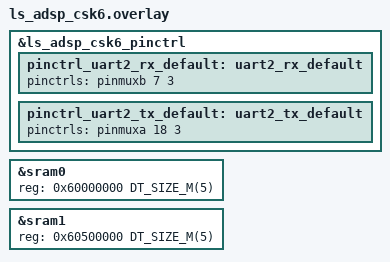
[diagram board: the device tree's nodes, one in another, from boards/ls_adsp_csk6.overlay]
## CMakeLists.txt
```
cmake_minimum_required(VERSION 3.20.0)

# SPDX-License-Identifier: Apache-2.0
#

if("${BOARD}" STREQUAL "ls_adsp_csk6")
set(ENV{ZEPHYR_TOOLCHAIN_VARIANT} "xcc-clang")
endif()

if("${BOARD}" STREQUAL "ls_adsp_csk6")
	message(STATUS " ${REMOTE_ZEPHYR_DIR} compiles as remote in this sample")
else()
	message(FATAL_ERROR "${BOARD} was not supported for this sample")
endif()
find_package(Zephyr HINTS $ENV{ZEPHYR_BASE})
project(sof_remote)


zephyr_include_directories(
  ./include
  ./include/luna/
  ./include/hifi/
  ./include/hifi_sim/
  ./include/opi_cpy/
  ./include/pilot/
  ./include/img/
  ./include/pilot_app/
)

if(NOT CONFIG_ALGO_RES_BIN)
	message(STATUS "CONFIG_ALGO_RES_BIN is not defined")
	zephyr_include_directories(./include/res/)
else()
message(STATUS "generating inc file")
	set(gen_dir ${ZEPHYR_BINARY_DIR}/include/generated)

	foreach(inc_file
		gesture.bin
		head_shoulder_detect.bin
		)
	generate_inc_file_for_target(
		app
		res/${inc_file}
		${gen_dir}/${inc_file}.inc
		)
	endforeach()

endif()

target_sources(app PRIVATE
    src/main.c
    src/opi_psram_cpy.c
    src/pilot_app.c
    src/test_cvtcolor.c
    src/cv_cvtcolor.c
  )


set(LIB_DIR  ${CMAKE_CURRENT_SOURCE_DIR}/lib)

target_link_libraries(app PUBLIC -Wl,--start-group 
						 -lgcc 
						 -lc 
						 -lm 
						 -lgloss 
						 -lminrt 
						 ${LIB_DIR}/libopi_cpy.a 
             			 ${LIB_DIR}/libhifi_dsp.a 
						 ${LIB_DIR}/libluna.a 
						 ${LIB_DIR}/libthinker.a 
						 ${LIB_DIR}/libpilot.a 
						 -Wl,--end-group)
```

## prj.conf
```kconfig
# CONFIG_SOF=y
CONFIG_LOG=y
CONFIG_LOG_PRINTK=y
CONFIG_LOG_MODE_MINIMAL=y

CONFIG_BUILD_OUTPUT_BIN=y
CONFIG_IPM=y
# Requires heap_info() be implemented, but no Zephyr wrapper
CONFIG_DEBUG_MEMORY_USAGE_SCAN=n

CONFIG_SCHED_DEADLINE=y
CONFIG_SCHED_CPU_MASK=y
CONFIG_SMP_BOOT_DELAY=y

CONFIG_DMA=y

CONFIG_CBPRINTF_FP_SUPPORT=y

CONFIG_ASSERT=y

CONFIG_EXTERNAL_LIBC=y
CONFIG_STDOUT_CONSOLE=n

CONFIG_STACK_SENTINEL=y

CONFIG_HEAP_MEM_POOL_SIZE=3145728
CONFIG_MAIN_STACK_SIZE=10240
```

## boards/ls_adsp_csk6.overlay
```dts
&ls_adsp_csk6_pinctrl{
        pinctrl_uart2_rx_default: uart2_rx_default {
			pinctrls = < &pinmuxb 7 3 >;
		};

		pinctrl_uart2_tx_default: uart2_tx_default {
			pinctrls = < &pinmuxa 18 3 >;
		};
};

&sram0 {
	reg = <0x60000000 DT_SIZE_M(5)>;
};

&sram1 {
	reg = <0x60500000 DT_SIZE_M(5)>;
};
```

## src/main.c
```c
/*
 * Copyright (c) 2020 Intel Corporation.
 *
 * SPDX-License-Identifier: Apache-2.0
 */

#include <zephyr.h>

#include <logging/log.h>
#include <w_pilot_err.h>
#include <pilot_app.h>
#include <venus_cp.h>
#include <luna_bits.h>
#include <ClockManager.h>

LOG_MODULE_REGISTER(main, LOG_LEVEL_DBG);

extern void test_cvt_yuv();
//CSK star app
int start_app(void)
{
	printk("Starting application_note\n");
	printk("Starting application_note2\n");
	test_cvt_yuv();
	// int ret_error = IPILOT_SUCCESS;
	// IPLT_INST ifr_inst = NULL;
	// //init
	// ret_error = INIT_ENGINE(&ifr_inst);
	// //set params
	// SET_PARMA_ENGINE(ifr_inst);
	// //test
	// CSK_test_function(ifr_inst);
	// //unint
	// ret_error = UINIT_ENGINE(ifr_inst);



	return 0;
}

extern void luna_init();
void sys_init(void)
{
    // enable NPU Clock
	__HAL_CRM_NPU_CLK_ENABLE();

    // release NPU
    if(IP_SYSCTRL->REG_SW_RESET_NPU.all){
        IP_SYSCTRL->REG_SW_RESET_NPU.all = 0xCAFE000C;
    }
    luna_init();

	uint32_t luna_val = *((volatile uint32_t *)(ADDR_LUNA_MODULE_ST));

	LOG_INF("luna_val: %d", luna_val);
}


extern void dma_init();
void main(void)
{

	LOG_INF("pilot app start");

	dma_init();
	sys_init();
	start_app();

}
```

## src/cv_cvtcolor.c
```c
#if defined(CSK6001)
#include <xtensa/config/core-isa.h>
#include <xtensa/tie/xt_core.h>
#include <xtensa/tie/xt_misc.h>
#include <xtensa/tie/xt_hifi3.h>
#include <xtensa/tie/xt_hifi4.h>
#else
#include "common.h"
#endif 

#include "hifi/NatureDSP_CV_math.h"

void cv_cvtcolor_yuv422vyuy_bgr888(const unsigned char* src, unsigned char* dst, unsigned int width, unsigned int height)
{
	int i, j, k;
	ae_int16x4 x0, x1, y0, v0, u0, xh0;
	ae_int32x2 z00, z01, z10, z11, z20, z21;
	ae_int24x2 z0, z1;
	ae_int16x4* px;
	ae_int24x2* pz;
	ae_int16x4 x256 = AE_MOVDA16(256);
	ae_int16x4 x128 = AE_MOVDA16(128);
	ae_int16x4 x359 = AE_MOVDA16(359);
	ae_int16x4 x183 = AE_MOVDA16(-183);
	ae_int16x4 x444 = AE_MOVDA16(444);
	ae_int16x4 x88 = AE_MOVDA16(-88);
	ae_int16x4 xff = AE_MOVDA16(0xff);
	ae_int32x2 zmask0 = AE_MOVDA32(0xff);
	ae_int32x2 zmask1 = AE_MOVDA32(0xff00);
	ae_int32x2 zmask2 = AE_MOVDA32(0xff0000);

	unsigned int z;
	const unsigned char* yuv_plane = src;
	unsigned char* rgb_plane = dst;

	px = (ae_int16x4*)yuv_plane;
	pz = (ae_int24x2*)rgb_plane;

	NASSERT(((uintptr_t)src & 0x7) == 0);
	NASSERT(((uintptr_t)dst & 0x7) == 0);
	NASSERT((width & 0x3) == 0);

	AE_L16X4_IP(xh0, px, 8);
	ae_valign zo_align = AE_ZALIGN64();

	for (int j = 0; j < ((height*width) >> 2); j++)
	{
		x0 = xh0;

		x1 = AE_AND16(x0, xff);
		y0 = AE_SLAA16S(x0, -8);
		y0 = AE_AND16(y0, xff);
		//y0 = AE_MOVINT16X4_FROMINT64((AE_SRLI64(AE_MOVINT64_FROMINT16X4(x0), 8)));

		x0 = AE_SEL16_7632(x1, x1);
		x1 = AE_SEL16_5410(x1, x1);
		v0 = AE_SEL16_7531(x0, x1);
		u0 = AE_SEL16_6420(x0, x1);
		v0 = AE_SUB16(v0, x128);
		u0 = AE_SUB16(u0, x128);

		//R
		AE_MUL16X4(z00, z01, y0, x256);
		//z10 = z00; z11 = z01;
		AE_MULA16X4(z00, z01, v0, x359);
		//G
		AE_MUL16X4(z10, z11, y0, x256);
		//z20 = z10; z21 = z11;
		AE_MULA16X4(z10, z11, v0, x183);
		AE_MULA16X4(z10, z11, u0, x88);
		//B
		AE_MUL16X4(z20, z21, y0, x256);
		AE_MULA16X4(z20, z21, u0, x444);
		AE_L16X4_IP(xh0, px, 8);

		//L->H:BGR0
		z00 = AE_AND32(AE_SLAA32S(z00, 8), zmask2);//H ((>>8)<<16)
		z10 = AE_AND32(z10, zmask1); //((>>8)<<8)
		z20 = AE_AND32(AE_SLAA32S(z20, -8), zmask0);//L
		z00 = AE_OR32(z00, AE_OR32(z10, z20));
		z0 = AE_MOVINT24X2_FROMF32X2(z00);
		AE_SA24X2_IP(z0, zo_align, pz);

		z01 = AE_AND32(AE_SLAA32S(z01, 8), zmask2);
		z11 = AE_AND32(z11, zmask1);
		z21 = AE_AND32(AE_SLAA32S(z21, -8), zmask0);
		z01 = AE_OR32(z01, AE_OR32(z11, z21));
		z1 = AE_MOVINT24X2_FROMF32X2(z01);
		AE_SA24X2_IP(z1, zo_align, pz);
	}
	AE_SA64POS_FP(zo_align, pz);
}
```

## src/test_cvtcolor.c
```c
#include "hifi/NatureDSP_CV_math.h"
#include "hifi_sim/NatureDSP_CV_math.h"


#include <luna.h>

#define ALIGNN(n,a)	((n+(a-1))&~(a-1))
#define MALLOCA(p, s, a)		(char*)(ALIGNN((uintptr_t)(p), a)); (p) = (char*)ALIGNN((uintptr_t)(p), a) + (s);
// #define printk printf;


void HIFI_SIM(cv_cvtcolor_yuv422vyuy_bgr888_dma)(const unsigned char* src, unsigned char* dst, unsigned int width, unsigned int height, unsigned int split_num,
	unsigned char* sharebuf, unsigned int sharesize)
{
	int i, j, k;
	int n = split_num; //8
	int block_size = width * height / n;
	unsigned char *p_block_s0 = sharebuf;
	unsigned char *p_block_s1 = p_block_s0 + block_size * 2;
	unsigned char *p_block_d0 = p_block_s1 + block_size * 2;
	unsigned char *p_block_d1 = p_block_d0 + block_size * 3;
	NASSERT(p_block_d1 - sharebuf <= sharesize);
	NASSERT((width * height) % n == 0);
	NASSERT((height / n) % 2 == 0);

	for (k = 0; k < n; k++)
	{
		unsigned char* p_block_s = (unsigned char*)src + k*block_size * 2;
		unsigned char* p_block_d = dst + k*block_size * 3;
		memcpy(p_block_s0, p_block_s, block_size * 2);
		cv_cvtcolor_yuv422vyuy_bgr888(p_block_s0, p_block_d0, width, height / n);
		memcpy(p_block_d, p_block_d0, block_size * 3);
	}
}

void cv_cvtcolor_yuv422vyuy_bgr888_dma(const unsigned char* src, unsigned char* dst, unsigned int width, unsigned int height, unsigned int split_num,
	unsigned char* sharebuf, unsigned int sharesize)
{
	int i, j, k;
	int n = split_num; //8
	int block_size = width * height / n;
	int block_size1 = block_size / 2;
	unsigned char *p_block_s0 = sharebuf;
	unsigned char *p_block_s1 = p_block_s0 + block_size * 2;
	unsigned char *p_block_d0 = p_block_s1 + block_size * 2;
	unsigned char *p_block_d1 = p_block_d0 + block_size * 3;
	NASSERT(p_block_d1 - sharebuf <= sharesize);
	NASSERT((width * height) % n == 0);
	NASSERT((height/ n) % 2 == 0);

	unsigned char* p_block_s = (unsigned char*)src + (n - 1)*block_size * 2;
	unsigned char* p_block_d = dst + (n - 1)*block_size * 3;
	unsigned char* p_block_ss, *p_block_dd;

	for (k = 0; k < n; k++)
	{
		if (k == 0)
		{
			p_block_ss = p_block_s0;
			p_block_dd = p_block_d0;
			//start_counter();
			dma_cpy_async(0, p_block_s0, p_block_s, block_size * 2);
			dma_wait_complete(0);
			p_block_s -= block_size * 2;
			//printk("counter1 = %d\n", get_counter());

			//start_counter();
			cv_cvtcolor_yuv422vyuy_bgr888(p_block_ss, p_block_dd, width, height / n / 2);
			//printk("counter1 = %d\n", get_counter());

			dma_cpy_async(0, p_block_s1, p_block_s, block_size * 2);
			cv_cvtcolor_yuv422vyuy_bgr888(p_block_ss + block_size / 2 * 2, p_block_dd + block_size / 2 * 3, width, height / n / 2);
			dma_wait_complete(0);
			p_block_s -= block_size * 2;
		}
		else if (k == n - 1)
		{
			p_block_ss = p_block_s1;
			p_block_dd = p_block_d1;

			dma_cpy_async(0, p_block_d, p_block_d0, block_size * 3);
			cv_cvtcolor_yuv422vyuy_bgr888(p_block_ss, p_block_dd, width, height / n / 2);
			dma_wait_complete(0);
			p_block_d -= block_size * 3;

			cv_cvtcolor_yuv422vyuy_bgr888(p_block_ss + block_size / 2 * 2, p_block_dd + block_size / 2 * 3, width, height / n / 2);

			//start_counter();
			dma_cpy_async(0, p_block_d, p_block_d1, block_size * 3);
			dma_wait_complete(0);
			p_block_d -= block_size * 3;
			//printk("counter1 = %d\n", get_counter());
		}
		else if (k % 2 == 0)
		{
			p_block_ss = p_block_s0;
			p_block_dd = p_block_d0;

			dma_cpy_async(0, p_block_s1, p_block_s, block_size * 2);
			cv_cvtcolor_yuv422vyuy_bgr888(p_block_ss, p_block_dd, width, height / n / 2);
			dma_wait_complete(0);

			dma_cpy_async(0, p_block_d, p_block_d1, block_size * 3);
			cv_cvtcolor_yuv422vyuy_bgr888(p_block_ss + block_size / 2 * 2, p_block_dd + block_size / 2 * 3, width, height / n / 2);
			dma_wait_complete(0);

			p_block_s -= block_size * 2;
			p_block_d -= block_size * 3;
		}
		else
		{
			p_block_ss = p_block_s1;
			p_block_dd = p_block_d1;

			dma_cpy_async(0, p_block_s0, p_block_s, block_size * 2);
			cv_cvtcolor_yuv422vyuy_bgr888(p_block_ss, p_block_dd, width, height / n / 2);
			dma_wait_complete(0);

			dma_cpy_async(0, p_block_d, p_block_d0, block_size * 3);
			cv_cvtcolor_yuv422vyuy_bgr888(p_block_ss + block_size / 2 * 2, p_block_dd + block_size / 2 * 3, width, height / n / 2);
			dma_wait_complete(0);

			p_block_s -= block_size * 2;
			p_block_d -= block_size * 3;
		}
	}
}


/*

test_cvt_yuv begin...
//CP:200M
//320x240
cv_cvtcolor_yuv422vyuy_bgr888_sim(psram) = 916745
cv_cvtcolor_yuv422vyuy_bgr888(psram) = 820280
cv_cvtcolor_yuv422vyuy_bgr888_sim(share) = 883423
cv_cvtcolor_yuv422vyuy_bgr888(share) = 326564
//640x480
cv_cvtcolor_yuv422vyuy_bgr888_dma_sim = 3726385
cv_cvtcolor_yuv422vyuy_bgr888_dma = 1471809
z1 = 0x6012f680, z2 = 0x60210680, size = 230400
test_cvt_yuv end...

*/
#define PSRAM_INST_SIZE (1*1024*1024)
#define SHARE_MEME_SIZE (640*1024)
static char g_psram_inst_buffer[PSRAM_INST_SIZE];
void test_cvt_yuv()
{
	printk("\ntest_cvt_yuv\n");
	
	clock_t last_t;
	char* p_psram = g_psram_inst_buffer;
	char* p_share = (char *)LUNA_SHARE_MEM_BASE;
	const unsigned int srcw = 640;
	const unsigned int srch = 480;
	const unsigned int dstw = 640;
	const unsigned int dsth = 480;
	unsigned int crc32;
	extern struct k_heap _system_heap;
// rzalloc(SOF_MEM_ZONE_RUNTIME, 0, SOF_MEM_CAPS_RAM, 3 * srcw*srch * 1);
	uint8_t* x = (uint8_t *)sys_heap_aligned_alloc(&_system_heap , 8,3 * srcw*srch * 1);
	ASSERT( x!=0);
	uint8_t* z1 = (uint8_t *)sys_heap_aligned_alloc(&_system_heap ,8,3 * srcw*srch * 1);
	ASSERT( z1!=0);
	uint8_t* z2 = (uint8_t *)sys_heap_aligned_alloc(&_system_heap ,8,3 * srcw*srch * 1);
		
	ASSERT( z2!=0);
	// for (int i = 0; i < 3 * srcw*srch; i++)
	// {
	// 	x[i] = rand() % 255;
	// }
	// ((unsigned char*)x)[0] = 129;

	printk("%s begin...\n", __FUNCTION__);

	//
	last_t = clock();
	// cv_cvtcolor_yuv422vyuy_bgr888_sim(x, z1, srcw / 2, srch / 2); 
	printk("cv_cvtcolor_yuv422vyuy_bgr888_sim(psram) = %d\n", clock() - last_t);

	last_t = clock();
	cv_cvtcolor_yuv422vyuy_bgr888(x, z2, srcw / 2, srch / 2);
	printk("cv_cvtcolor_yuv422vyuy_bgr888(psram) = %d\n", clock() - last_t);

	ASSERT(test_cmp(z1, z2, 3 * dstw / 2 * dsth / 2, 0x11) == 0);

	//
	last_t = clock();
	// cv_cvtcolor_yuv422vyuy_bgr888_sim((unsigned char*)p_share, (unsigned char*)p_share, srcw / 2, srch / 2);
	printk("cv_cvtcolor_yuv422vyuy_bgr888_sim(share) = %d\n", clock() - last_t);

	last_t = clock();
	cv_cvtcolor_yuv422vyuy_bgr888((unsigned char*)p_share, (unsigned char*)p_share, srcw / 2, srch / 2); 
	printk("cv_cvtcolor_yuv422vyuy_bgr888(share) = %d\n", clock() - last_t);

	//dma
	cv_cvtcolor_yuv422vyuy_bgr888(x, z1, srcw, srch);

	last_t = clock();
	// cv_cvtcolor_yuv422vyuy_bgr888_dma_sim(x, z2, srcw, srch, 16, (unsigned char*)p_share, 640 * 1024);
	printk("cv_cvtcolor_yuv422vyuy_bgr888_dma_sim = %d\n", clock() - last_t);
	// NASSERT(test_cmp(z1, z2, 3 * dstw * dsth, 0x11) == 0);

	//memcpy(z2, x, srcw*srch * 2);
	dma_cpy_async(0, z2, x, srcw*srch * 2);
	dma_wait_complete(0);

	last_t = clock();
	cv_cvtcolor_yuv422vyuy_bgr888_dma(z2, z2, srcw, srch, 16, (unsigned char*)p_share, 640 * 1024); 
	printk("cv_cvtcolor_yuv422vyuy_bgr888_dma = %d\n", clock() - last_t);

	// NASSERT(test_cmp(z1, z2, 3 * dstw * dsth, 0x11) == 0);
	printk("z1 = 0x%x, z2 = 0x%x, size = %d\n", z1, z2, 3 * dstw / 2 * dsth / 2);

#if 1
	// dma_cpy_async(0, z2, cvtcolor_yuv422vyuy_resource, srcw*srch * 2);
	// dma_wait_complete(0);
	last_t = clock();
	cv_cvtcolor_yuv422vyuy_bgr888_dma(z2, z2, srcw, srch, 16, (unsigned char*)p_share, 640 * 1024);
	printk("cv_cvtcolor_yuv422vyuy_bgr888_dma = %d\n", clock() - last_t);
	// crc32 = iv_crc32_calc(z2, srcw*srch * 3, 0);
	printk("crc32 = 0x%x\n", crc32);
	NASSERT(crc32 = 0x42d81e47);
#endif 

	printk("%s end...\n", __FUNCTION__);
}
```
